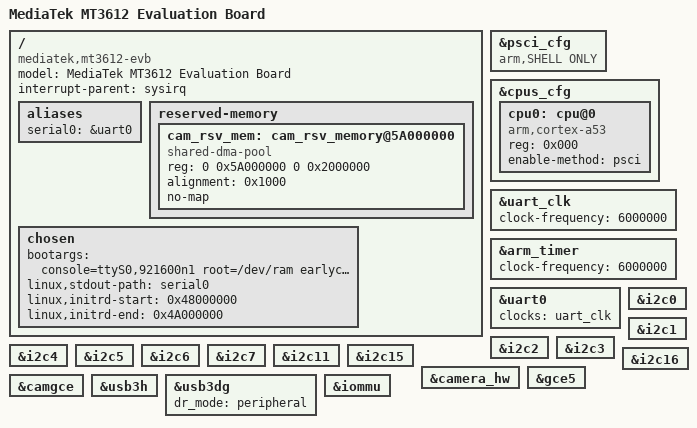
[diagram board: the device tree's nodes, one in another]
/*
 * Copyright (c) 2018 MediaTek Inc.
 * Author: Yung-Chi Chen <yung-chi.chen@mediatek.com>
 *
 * This program is free software; you can redistribute it and/or modify
 * it under the terms of the GNU General Public License version 2 as
 * published by the Free Software Foundation.
 *
 * This program is distributed in the hope that it will be useful,
 * but WITHOUT ANY WARRANTY; without even the implied warranty of
 * MERCHANTABILITY or FITNESS FOR A PARTICULAR PURPOSE.  See the
 * GNU General Public License for more details.
 */

/dts-v1/;

#include "mt3612-fpga-system.dtsi"
#include "mt3612-fpga-peri.dtsi"
#include "mt3612-fpga-mm.dtsi"
#include "mt3612-fpga-test.dtsi"
#include "mt3612-fpga-camera-i2c.dtsi"
#include "mt3612-fpga-camera.dtsi"

/ {
	model = "MediaTek MT3612 Evaluation Board";
	compatible = "mediatek,mt3612-evb", "mediatek,mt3612";
	interrupt-parent = <&sysirq>;
	#address-cells = <2>;
	#size-cells = <2>;

	aliases {
		serial0 = &uart0;
	};

	reserved-memory {
		#address-cells = <2>;
		#size-cells = <2>;
		ranges;

		cam_rsv_mem: cam_rsv_memory@5A000000 {
			compatible = "shared-dma-pool";
			reg = <0 0x5A000000 0 0x2000000>;
			alignment = <0x1000>;
			no-map;
		};

	};

	chosen {
		bootargs = "console=ttyS0,921600n1 root=/dev/ram \
			earlycon=mtk8250,0x11020000,921600n8 loglevel=8";
		linux,stdout-path = "serial0";
		linux,initrd-start = <0x48000000>;
		linux,initrd-end = <0x4A000000>;
	};

};


&psci_cfg{
	compatible	= "arm,SHELL ONLY";
};

&cpus_cfg{
	#address-cells = <1>;
	#size-cells = <0>;

	cpu0: cpu@0 {
		device_type = "cpu";
		compatible = "arm,cortex-a53";
		reg = <0x000>;
		enable-method = "psci";
	};

};

&uart_clk{
	clock-frequency = <6000000>;
};

&arm_timer {
	clock-frequency = <6000000>;
};

&uart0 {
	clocks = <&uart_clk>;
	status = "okay";
};

&i2c0 {
	status = "okay";
};

&i2c1 {
	status = "okay";
};

&i2c2 {
	status = "okay";
};

&i2c3 {
	status = "okay";
};

&i2c4 {
	status = "okay";
};

&i2c5 {
	status = "okay";
};

&i2c6 {
	status = "okay";
};

&i2c7 {
	status = "okay";
};

&i2c1 {
	status = "okay";
};

&i2c5 {
	status = "okay";
};

&i2c11 {
	status = "okay";
};
&i2c15 {
	status = "okay";
};
&i2c16 {
	status = "okay";
};
&camera_hw {
	status = "okay";
};

&gce5 {
	status = "okay";
};

&camgce {
	status = "okay";
};

&usb3h {
	status = "okay";
};

&usb3dg {
	dr_mode = "peripheral";
	status = "okay";
};

&iommu {
	status = "okay";
};
